# MCU_NAVSS0_UDMASS_PSILSS_CFG0_PROXY register map
Vendor: Texas Instruments
Peripheral module from a debugger description file (folder am65x).
Registers are 32-bit, read-write, reset 0x0 unless marked. A register's access mark holds for its fields unless they carry their own. Offsets are as the file gives them; lines under a group give offsets from that group; [hi:lo] are bit positions; {n}, {i} and the like mark numbered series; 'fields as' and 'values as' point back to an identical list; <NAME> marks a mode.

## MCU_NAVSS0_UDMASS_PSILSS_CFG0_PROXY
0x00 PSIL_CFG_PROXY_REVISION ro reset 0x66C00100 — The Revision Register contains the major and minor revisions for the module.
  [31:0] REV — TI internal data.
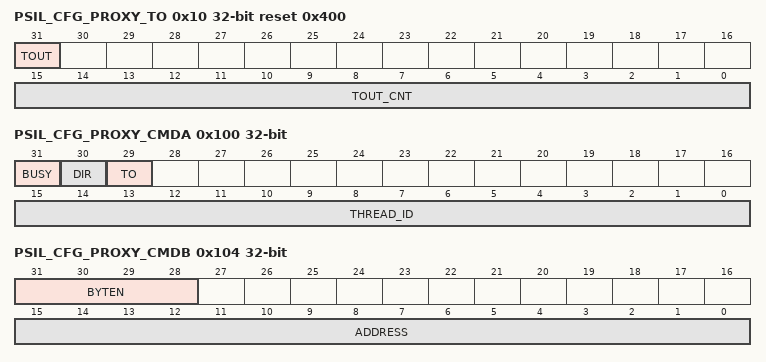
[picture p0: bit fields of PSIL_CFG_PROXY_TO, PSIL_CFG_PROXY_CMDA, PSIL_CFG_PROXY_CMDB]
0x10 PSIL_CFG_PROXY_TO reset 0x400 — The PSI-L proxy timeout register controls the timeout watchdog and reports timeout occurrances on PSI-L configuration transactions issued by the built in PSI-L proxy.
  [31] TOUT — Timeout occurred. When set indicates that a timeout has occurred on a configuration access. Once set, this bit is persistent until manually cleared.
  [15:0] TOUT_CNT — Timeout period. Specifies how many cycles to wait before closing up a configuration read or write transaction and asserting the TOUT bit
0x100 PSIL_CFG_PROXY_CMDA — The Command Register A contains the busy indicator, direction, and thread number for the configuration transaction.
  [31] BUSY — Indication that a configuration read or write is in progress 0h = No transaction is in progress 1h = Transaction is in progress
  [30] DIR — Direction of configuration transaction 0h = Write transaction 1h = Read transaction
  [29] TO — Indication that a timeout occurred. This bit should be written to 0h on each new transaction. 0h = Transaction completed normally 1h = Timeout occurred
  [15:0] THREAD_ID — Thread ID to which configuration read or write is being sent. The thread ID mapping is shown in
0x104 PSIL_CFG_PROXY_CMDB — The Command Register B contains the byte enables and word address for the configuration transaction.
  [31:28] BYTEN — Byte enables to use for configuration read or write
  [15:0] ADDRESS — Word (32-bit) address within thread configuration space for transaction 0h = Peer thread ID register ( 1h = Peer credit register ( 2h = Enable register ( 40h = Capabilities register ( 400h = Static TR register
0x108 PSIL_CFG_PROXY_WDATA — The Write Data Register contains the data which is to be written during the configuration transaction.
  [31:0] WDATA — Configuration data word to be written
0x140 PSIL_CFG_PROXY_RDATA — The Read Data Register contains the data which was read back during the configuration transaction.
  [31:0] RDATA — Configuration data word that was read
